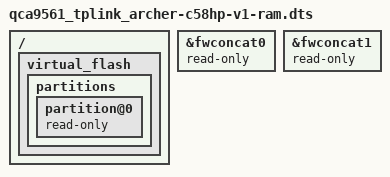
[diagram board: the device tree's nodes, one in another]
// SPDX-License-Identifier: GPL-2.0-or-later OR MIT

#include "qca9561_tplink_archer-c58hp-v1.dts"

/* RAM testing: preserve all physical and logical flash contents. */
&fwconcat0 {
	read-only;
};

&fwconcat1 {
	read-only;
};

/ {
	virtual_flash {
		partitions {
			partition@0 {
				read-only;
			};
		};
	};
};
